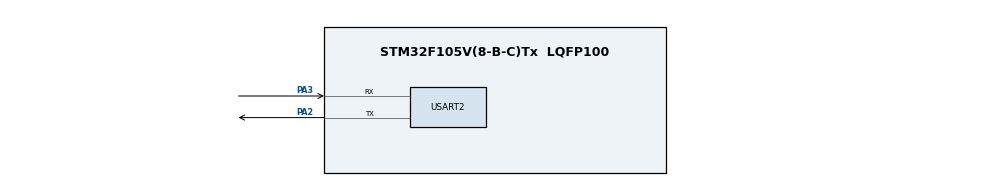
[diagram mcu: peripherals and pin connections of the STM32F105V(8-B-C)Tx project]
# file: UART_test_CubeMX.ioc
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Dma.Request0=USART2_RX
Dma.USART2_RX.0.Direction=DMA_PERIPH_TO_MEMORY
Dma.USART2_RX.0.Instance=DMA1_Channel6
Dma.USART2_RX.0.MemDataAlignment=DMA_MDATAALIGN_BYTE
Dma.USART2_RX.0.MemInc=DMA_MINC_ENABLE
Dma.USART2_RX.0.Mode=DMA_NORMAL
Dma.USART2_RX.0.PeriphDataAlignment=DMA_PDATAALIGN_BYTE
Dma.USART2_RX.0.PeriphInc=DMA_PINC_DISABLE
Dma.USART2_RX.0.Priority=DMA_PRIORITY_LOW
Mcu.Family=STM32F1
Mcu.Name=STM32F105V(8-B-C)Tx
Mcu.Package=LQFP100
NVIC.DMA1_Channel6_IRQn=true\:0\:0\:false\:false\:true\:false\:true
NVIC.PriorityGroup=NVIC_PRIORITYGROUP_4
PA2.Mode=Asynchronous
PA2.Signal=USART2_TX
PA3.Mode=Asynchronous
PA3.Signal=USART2_RX
ProjectManager.HeapSize=0x200
ProjectManager.StackSize=0x400
ProjectManager.TargetToolchain=MDK-ARM V5
RCC.USBFreq_Value=10666666.666666666
USART2.VirtualMode=VM_ASYNC
VP_SYS_VS_ND.Mode=No_Debug
board=custom

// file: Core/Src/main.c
#include "main.h"
#include <stdio.h>
#include <string.h>

UART_HandleTypeDef huart2;
DMA_HandleTypeDef hdma_usart2_rx;

void SystemClock_Config(void);
static void MX_GPIO_Init(void);
static void MX_DMA_Init(void);
static void MX_USART2_UART_Init(void);

char rxData[19];

int main(void)
{
  HAL_Init(); /* Reset of all peripherals, Initializes the Flash interface and the Systick. */
  SystemClock_Config(); /* Configure the system clock */

  /* Initialize all configured peripherals */
  MX_GPIO_Init();
  MX_DMA_Init();
  MX_USART2_UART_Init();

	char txData[20]="Hello World\r\n";

	HAL_UART_Transmit(&huart2,(uint8_t*)txData, strlen(txData),10);

  /* Infinite loop */
  while (1)
  {
		HAL_UART_Receive_DMA(&huart2, (uint8_t*)rxData, 18);
		//HAL_Delay(500);
  }
}

void SystemClock_Config(void)
{
  RCC_OscInitTypeDef RCC_OscInitStruct = {0};
  RCC_ClkInitTypeDef RCC_ClkInitStruct = {0};

  /** Initializes the RCC Oscillators according to the specified parameters
  * in the RCC_OscInitTypeDef structure.
  */
  RCC_OscInitStruct.OscillatorType = RCC_OSCILLATORTYPE_HSI;
  RCC_OscInitStruct.HSIState = RCC_HSI_ON;
  RCC_OscInitStruct.HSICalibrationValue = RCC_HSICALIBRATION_DEFAULT;
  RCC_OscInitStruct.PLL.PLLState = RCC_PLL_NONE;
  RCC_OscInitStruct.PLL2.PLL2State = RCC_PLL_NONE;
  if (HAL_RCC_OscConfig(&RCC_OscInitStruct) != HAL_OK)
  {
    Error_Handler();
  }
  /** Initializes the CPU, AHB and APB buses clocks
  */
  RCC_ClkInitStruct.ClockType = RCC_CLOCKTYPE_HCLK|RCC_CLOCKTYPE_SYSCLK
                              |RCC_CLOCKTYPE_PCLK1|RCC_CLOCKTYPE_PCLK2;
  RCC_ClkInitStruct.SYSCLKSource = RCC_SYSCLKSOURCE_HSI;
  RCC_ClkInitStruct.AHBCLKDivider = RCC_SYSCLK_DIV1;
  RCC_ClkInitStruct.APB1CLKDivider = RCC_HCLK_DIV1;
  RCC_ClkInitStruct.APB2CLKDivider = RCC_HCLK_DIV1;

  if (HAL_RCC_ClockConfig(&RCC_ClkInitStruct, FLASH_LATENCY_0) != HAL_OK)
  {
    Error_Handler();
  }
  /** Configure the Systick interrupt time
  */
  __HAL_RCC_PLLI2S_ENABLE();
}

static void MX_GPIO_Init(void)
{
  /* GPIO Ports Clock Enable */
  __HAL_RCC_GPIOA_CLK_ENABLE();
}

static void MX_USART2_UART_Init(void)
{
  huart2.Instance = USART2;
  huart2.Init.BaudRate = 115200;
  huart2.Init.WordLength = UART_WORDLENGTH_8B;
  huart2.Init.StopBits = UART_STOPBITS_1;
  huart2.Init.Parity = UART_PARITY_NONE;
  huart2.Init.Mode = UART_MODE_TX_RX;
  huart2.Init.HwFlowCtl = UART_HWCONTROL_NONE;
  huart2.Init.OverSampling = UART_OVERSAMPLING_16;
	//設定中斷優先順序
	HAL_NVIC_SetPriority(USART2_IRQn, 0, 0);
	HAL_NVIC_EnableIRQ(USART2_IRQn);

  if (HAL_UART_Init(&huart2) != HAL_OK)
  {
    Error_Handler();
  }
}

static void MX_DMA_Init(void)
{
  /* DMA controller clock enable */
  __HAL_RCC_DMA1_CLK_ENABLE();

  /* DMA interrupt init */
  /* DMA1_Channel6_IRQn interrupt configuration */
  HAL_NVIC_SetPriority(DMA1_Channel6_IRQn, 0, 0);
  HAL_NVIC_EnableIRQ(DMA1_Channel6_IRQn);

}

void HAL_UART_RxCpltCallback(UART_HandleTypeDef *huart)
{
  /* Prevent unused argument(s) compilation warning */
  UNUSED(huart);
  /* NOTE: This function should not be modified, when the callback is needed,
           the HAL_UART_RxCpltCallback could be implemented in the user file
   */
	//HAL_UART_Transmit(huart,(uint8_t*)"RxCpltCallback", strlen("RxCpltCallback"),10);
	//sprintf(rxData,"%s\n",rxData);
	HAL_UART_Transmit(&huart2,(uint8_t*)rxData, strlen(rxData),10);
	HAL_UART_Transmit(&huart2,(uint8_t*)"\r\n", strlen("\r\n"),10);
}

void Error_Handler(void)
{
  /* USER CODE BEGIN Error_Handler_Debug */
  /* User can add his own implementation to report the HAL error return state */
  __disable_irq();
  while (1)
  {
		HAL_UART_Transmit(&huart2,(uint8_t*)"Error_Handler", strlen("Error_Handler"),10);
  }
  /* USER CODE END Error_Handler_Debug */
}
